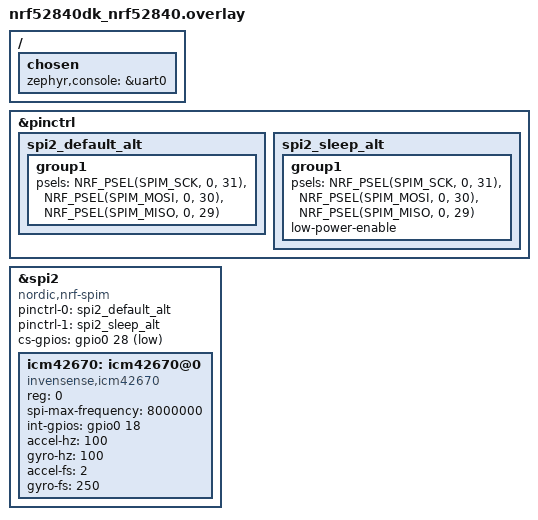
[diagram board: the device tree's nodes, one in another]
/*
 * Copyright (c) 2024 Nordic Semiconductor ASA
 *
 * SPDX-License-Identifier: Apache-2.0
 */

/ {
	chosen {
		zephyr,console = &uart0;
	};
};

&pinctrl {
	spi2_default_alt: spi2_default_alt {
		group1 {
			psels = <NRF_PSEL(SPIM_SCK, 0, 31)>,    /* P0.31 */
				<NRF_PSEL(SPIM_MOSI, 0, 30)>,   /* P0.30 */
				<NRF_PSEL(SPIM_MISO, 0, 29)>;   /* P0.29 */
		};
	};

	spi2_sleep_alt: spi2_sleep_alt {
		group1 {
			psels = <NRF_PSEL(SPIM_SCK, 0, 31)>,
				<NRF_PSEL(SPIM_MOSI, 0, 30)>,
				<NRF_PSEL(SPIM_MISO, 0, 29)>;
			low-power-enable;
		};
	};
};

&spi2 {
	status = "okay";
	compatible = "nordic,nrf-spim";
	pinctrl-0 = <&spi2_default_alt>;
	pinctrl-1 = <&spi2_sleep_alt>;
	pinctrl-names = "default", "sleep";
	cs-gpios = <&gpio0 28 GPIO_ACTIVE_LOW>;    /* P0.28 */

	icm42670: icm42670@0 {
		compatible = "invensense,icm42670";
		reg = <0>;
		spi-max-frequency = <8000000>;         /* Reduced to 8MHz for stability */
		int-gpios = <&gpio0 18 GPIO_ACTIVE_HIGH>;  /* P0.18 for INT */
		status = "okay";
		
		/* Required properties based on binding file */
		accel-hz = <100>;    /* Reduced to 100 Hz for initial testing */
		gyro-hz = <100>;     /* Reduced to 100 Hz for initial testing */
		accel-fs = <2>;      /* Reduced to ±2g for initial testing */
		gyro-fs = <250>;     /* Reduced to 250 dps for initial testing */
	};
};
